# CPUSS_1.0 register map
Vendor: Texas Instruments
Peripheral module from a debugger description file (folder mspm0l211x_l112x).
Registers are 32-bit, read-only, no defined reset value unless marked. A register's access mark holds for its fields unless they carry their own. Offsets are as the file gives them; lines under a group give offsets from that group; [hi:lo] are bit positions; {n}, {i} and the like mark numbered series; 'fields as' and 'values as' point back to an identical list; <NAME> marks a mode.

## CPUSS
0x10E0 CPUSS_EVT_MODE — Event Mode
  [1:0] INT_CFG — Event line mode select
    0=DISABLE (The interrupt or event line is disabled.); 1=SOFTWARE (Event handled by software. Software must clear the associated RIS flag.); 2=HARDWARE (Event handled by hardware. The hardware (another module) clears automatically the associated RIS flag.)
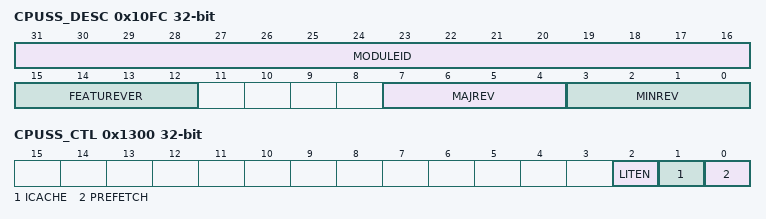
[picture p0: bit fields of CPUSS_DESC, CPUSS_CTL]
0x10FC CPUSS_DESC — Module Description
  [31:16] MODULEID — Module identification contains a unique peripheral identification number. The assignments are maintained in a central database for all of the platform modules to ensure uniqueness.
  [15:12] FEATUREVER — Feature Set for the module *instance*
  [7:4] MAJREV — Major rev of the IP
  [3:0] MINREV — Minor rev of the IP
0x1300 CPUSS_CTL rw — Prefetch/Cache control
  [2] LITEN — Literal caching and prefetch enable. This bit is a subset of ICACHE/PREFETCH bit i.e. literal caching or literal prefetching will only happen if ICACHE or PREFETCH bits have been set respectively When enabled, the cache and prefetcher structures inside CPUSS will cache and prefetch literals When disabled, the cache and prefetcher structures inside CPUSS will not cache and prefetch literals
    0=DISABLE (Literal caching disabled); 1=ENABLE (Literal caching enabled)
  [1] ICACHE — Used to enable/disable Instruction caching on flash access.
    0=DISABLE (Disable instruction caching.); 1=ENABLE (Enable instruction caching.)
  [0] PREFETCH — Used to enable/disable instruction prefetch to Flash.
    0=DISABLE (Disable instruction prefetch.); 1=ENABLE (Enable instruction prefetch.)
